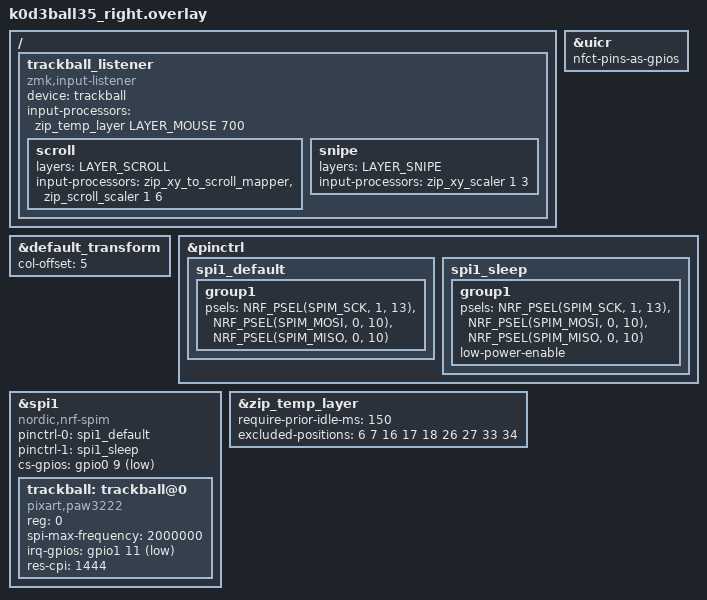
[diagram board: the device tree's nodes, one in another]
/*
 * Right half (split central, 15 finger + 2 thumb keys - the inner pair since r2.3,
 * the outer position is the ball pocket - carries the PAW3222
 * trackball sensor module for the 19.05 mm ball, tilted 65 degrees beside it).
 *
 * Row and column pins are shared with the left half and live in k0d3ball35.dtsi
 * (COL0..COL4 = pro_micro 4..8, ROW0..ROW3 = pro_micro 21, 20, 19, 18). Sensor:
 *   TB_SCLK  pro_micro 15 = P1.13
 *   TB_SDIO  pro_micro 16 = P0.10  (3-wire SPI: MOSI and MISO on the same pin)
 *   TB_NCS   pro_micro 10 = P0.09
 *   TB_MOT   pro_micro 14 = P1.11
 */

#include "k0d3ball35.dtsi"
#include <dt-bindings/input/input-event-codes.h>
#include <input/processors.dtsi>
#include <dt-bindings/zmk/input_transform.h>

#define LAYER_MOUSE  4
#define LAYER_SCROLL 5
#define LAYER_SNIPE  6

&default_transform {
    col-offset = <5>;
};

/* P0.09 / P0.10 are the NFC antenna pins; use them as plain GPIO. */
&uicr {
    nfct-pins-as-gpios;
};

&pinctrl {
    spi1_default: spi1_default {
        group1 {
            psels = <NRF_PSEL(SPIM_SCK, 1, 13)>,
                    <NRF_PSEL(SPIM_MOSI, 0, 10)>,
                    <NRF_PSEL(SPIM_MISO, 0, 10)>;
        };
    };

    spi1_sleep: spi1_sleep {
        group1 {
            psels = <NRF_PSEL(SPIM_SCK, 1, 13)>,
                    <NRF_PSEL(SPIM_MOSI, 0, 10)>,
                    <NRF_PSEL(SPIM_MISO, 0, 10)>;
            low-power-enable;
        };
    };
};

&spi1 {
    status = "okay";
    compatible = "nordic,nrf-spim";
    pinctrl-0 = <&spi1_default>;
    pinctrl-1 = <&spi1_sleep>;
    pinctrl-names = "default", "sleep";
    cs-gpios = <&gpio0 9 GPIO_ACTIVE_LOW>;

    trackball: trackball@0 {
        status = "okay";
        compatible = "pixart,paw3222";
        reg = <0>;
        spi-max-frequency = <2000000>;
        irq-gpios = <&gpio1 11 (GPIO_ACTIVE_LOW | GPIO_PULL_UP)>;
        /* 19.05 mm ball. The sensor counts surface travel, and a rigid sphere moves
         * its surface by the same mm at the sensor as under the thumb whatever its
         * size, so counts per mm of thumb travel do not change. What changes is the
         * stroke: the thumb runs off a smaller sphere sooner and the light ball does
         * not coast after a flick, so each stroke moves less surface. To cover the
         * same screen distance per stroke the 19 mm ball needs about 30 percent more
         * CPI than the 25 mm setup (400), so the target is about 600 counts per inch
         * of thumb travel on both axes.
         *
         * The tilt costs the sensor's short axis cos(65) of that (see BALL_TILT below), so
         * the sensor runs at 600 / cos(65) = 1420, rounded to the driver's 38-count step:
         * 1444 (38 x 38). The short axis then reads 1444 x 0.423 = 610, and BALL_TILT brings
         * the fast one down to the same 611. Tune, see issues/fw-cpi-tuning-19mm.md. */
        res-cpi = <1444>;
    };
};

/* Keys that keep the auto mouse layer alive while it is active (mouse buttons,
 * scroll and snipe modifiers on the right half). Positions follow the matrix
 * transform order in k0d3ball35.dtsi (35 keys): 6 7 = scroll/snipe layer keys,
 * 16 17 18 = left/right/middle click, 26 27 = back/forward, 33 34 = the two
 * right thumb keys. */
&zip_temp_layer {
    require-prior-idle-ms = <150>;
    excluded-positions = <6 7 16 17 18 26 27 33 34>;
};

/* Axes and scale for the 65 degree tilt. The sensor sits beside the ball towards layout +x
 * (under the middle-finger column, hardware/trackball-cradle sensor_az 180) and looks at it
 * 25 degrees below the equator instead of at the bottom pole. With the ball centre at the origin
 * it sees the point p = R (sin 65, 0, -cos 65). The thumb on top turns the ball about a
 * horizontal axis, and a surface point moves at w x p:
 *   thumb along x (screen left/right): rotation about the y axis. p lies on a great circle of
 *     that rotation, so it moves at the full thumb speed, in the tilt plane: that is the
 *     module's 7.4 mm edge, the sensor's Y axis.
 *   thumb along y (screen up/down): rotation about the x axis. p is only R cos 65 from that
 *     axis, so it moves at cos 65 = 0.423 of the thumb speed, along the module's 13.4 mm edge:
 *     the sensor's X axis.
 * So the sensor's Y axis is the fast one and carries the SCREEN X, and its X axis is short and
 * carries the SCREEN Y. Three steps, in this order:
 *   1. res-cpi is raised by 1 / cos 65 so the short axis reaches the target,
 *   2. the fast sensor axis is scaled down by cos 65 = 0.4226 ~ 11/26 (0.4231), still in the
 *      sensor's own frame (zip_y_scaler),
 *   3. the axes are swapped into screen axes (XY_SWAP; the transform swaps first and inverts
 *      the swapped axis afterwards).
 * Until the 2026-11-12 review this block still described the sensor at +y (r2.4, before it
 * moved to +x) and had no swap: left/right and up/down would have come out exchanged.
 * The Y sign follows from turning the module a quarter turn from its r2.4 position; neither
 * sign has been seen on hardware yet. Wrong direction after assembly: toggle
 * INPUT_TRANSFORM_X_INVERT / INPUT_TRANSFORM_Y_INVERT here (they act on the SCREEN axes).
 * Cursor fast up/down and slow sideways: the module's axes are the other way round, move the
 * scale to zip_x_scaler. Layer overrides replace the base processors, so each one repeats
 * BALL_TILT. Starting values from geometry; tune on hardware, issues/fw-cpi-tuning-19mm.md and
 * issues/fw-cursor-axis-verification.md. */
#define BALL_TILT <&zip_y_scaler 11 26>, <&zip_xy_transform (INPUT_TRANSFORM_XY_SWAP | INPUT_TRANSFORM_Y_INVERT)>

/ {
    trackball_listener: trackball_listener {
        compatible = "zmk,input-listener";
        device = <&trackball>;
        input-processors = BALL_TILT, <&zip_temp_layer LAYER_MOUSE 700>;

        scroll {
            layers = <LAYER_SCROLL>;
            input-processors = BALL_TILT, <&zip_xy_to_scroll_mapper>, <&zip_scroll_scaler 1 6>;
        };

        snipe {
            layers = <LAYER_SNIPE>;
            input-processors = BALL_TILT, <&zip_xy_scaler 1 3>;
        };
    };
};
